# dm648_cslr_3gss register map
Vendor: Texas Instruments
Peripheral module from a debugger description file.
Registers are 32-bit, access not given, reset 0x0 unless marked. A register's access mark holds for its fields unless they carry their own. Offsets are as the file gives them; lines under a group give offsets from that group; [hi:lo] are bit positions; {n}, {i} and the like mark numbered series; 'fields as' and 'values as' point back to an identical list; <NAME> marks a mode.

## CPSW_3GSS — 3GSS
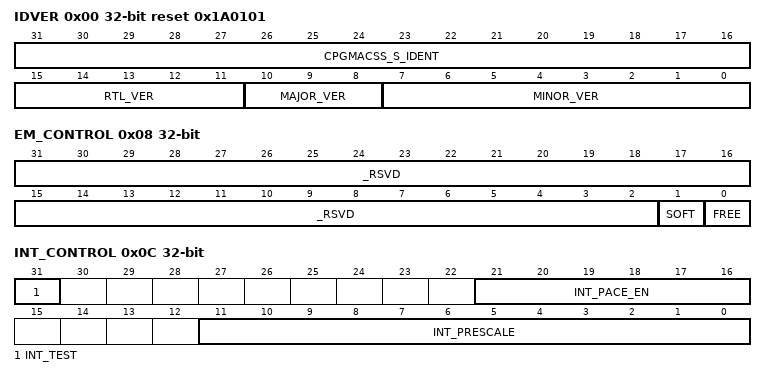
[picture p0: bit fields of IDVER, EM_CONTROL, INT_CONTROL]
0x00 IDVER ro reset 0x1A0101 — version id register
  [31:16] CPGMACSS_S_IDENT — 3GSS Identification value
  [15:11] RTL_VER — 3GSS RTL_version register
  [10:8] MAJOR_VER — 3GSS Major version register
  [7:0] MINOR_VER — 3GSS Minor Version register
0x04 SOFT_RESET
  [0] SOFT_RESET rw — Software reset  Writing a one to this bit causes the CPSW_3GSS_S logic to be reset (INT, REGS, MDIO). Software reset occurs on the clock following the register bit write.
0x08 EM_CONTROL — Emulation control
  [31:2] _RSVD — These bits are not used (access N)
  [1] SOFT rw — Emulation Soft Bit
    0=?
  [0] FREE rw — Emulation Free Bit
0x0C INT_CONTROL — Interrupt Control Register
  [31] INT_TEST rw — Interrupt Test  Test bit to the interrupt pacing blocks
  [21:16] INT_PACE_EN rw — Interrupt Pacing Enable Bus int_pace_en[0]  Enables C0_Rx_Pulse Pacing (0 is pacing bypass) int_pace_en[1]  Enables C0_Tx_Pulse Pacing (0 is pacing bypass) int_pace_en[2]  Enables C1_Rx_Pulse Pacing (0 is pacing bypass) int_pace_en[3]  Enables C1_Tx_Pulse Pacing (0 is pacing bypass) int_pace_en[4]  Enables C2_Rx_Pulse Pacing (0 is pacing bypass) int_pace_en[5]  Enables C2_Tx_Pulse Pacing (0 is pacing bypass)
  [11:0] INT_PRESCALE rw — Interrupt Counter Prescaler  The number of VBUSP_CLK periods in 4us.
    0=?; 0=?
0x10 RX_THRESH_EN — Receive Threshold Enable
  [7:0] RX_THRESH_EN rw — Receive Threshold Enable - Each bit in this register corresponds to the bit in the receive threshold interrupt that is enabled to generate an interrupt on RX_THRESH_PULSE.
    0=?
0x14 RX_EN — Receive Interrupt Enable
  [7:0] RX_EN rw — Receive Enable - Each bit in this register corresponds to the bit in the rx interrupt that is enabled to generate an interrupt on RX_PULSE.
    0=?
0x18 TX_EN — Transmit Interrupt Enable
  [7:0] TX_EN rw — Transmit Enable - Each bit in this register corresponds to the bit in the tx interrupt that is enabled to generate an interrupt on TX_PULSE.
    0=?; 0=?
0x1C MISC_EN — Misc Interrupt Enable
  [3:0] MISC_EN rw — Misc Enable - Each bit in this register corresponds to the miscellaneous interrupt (stat_pend, host_pend, mdio_linkint, mdio_userint) that is enabled to generate an interrupt on Misc_PULSE.
0x20 RX_THRESH_STAT — Receive Threshold Status
  [7:0] RX_THRESH_STAT ro — Receive Threshold Masked Interrupt Status - Each bit in this read only register corresponds to the bit in the receive threshold interrupt that is enabled and generating an interrupt on RX_THRESH_PULSE.
    0=?
0x24 RX_STAT — Receive Status Register
  [7:0] RX_STAT ro — Receive Masked Interrupt Status - Each bit in this read only register corresponds to the bit in the Rx interrupt that is enabled and generating an interrupt on RX_PULSE.
0x28 TX_STAT — Transmit status register
  [7:0] TX_STAT ro — Transmit Masked Interrupt Status - Each bit in this read only register corresponds to the bit in the Tx interrupt that is enabled and generating an interrupt on TX_PULSE .
0x2C MISC_STAT — Misc Interrupt status register
  [7:0] MISC_STAT ro — Misc Masked Interrupt Status - Each bit in this register corresponds to the miscellaneous interrupt (stat_pend, host_pend, mdio_linkint, mdio_userint) that is enabled and generating an interrupt on MISC_PULSE .
0x30 RX_IMAX — Receive Interrupts per millisecond register
  [5:0] RX_IMAX rw — Receive Interrupts per Millisecond - The maximum number of interrupts per millisecond generated on RX_PULSE if pacing is enabled for this interrupt.
0x34 TX_IMAX — Transmit Interrupts per millisecond register
  [5:0] TX_IMAX rw — Receive Interrupts per Millisecond - The maximum number of interrupts per millisecond generated on RX_PULSE if pacing is enabled for this interrupt.
    0=?
